# TC37XPD register map
Vendor: Infineon; Series: ATVMC; File version: 100
CPU: other r0p0, little endian, MPU, FPU, vendor SysTick, 4 interrupt priority bits
Registers are 32-bit, read-write, reset 0x0 unless marked. A register's access mark holds for its fields unless they carry their own. Offsets are from the block's base; [hi:lo] are bit positions; lines under a group give offsets from that group; {n}, {i} and the like mark numbered series.

## CAN0 (part 3 of 3) — CAN
Base 0xF0200000
{0x8100+0x400*i} N[{i}] (i=0..3) group
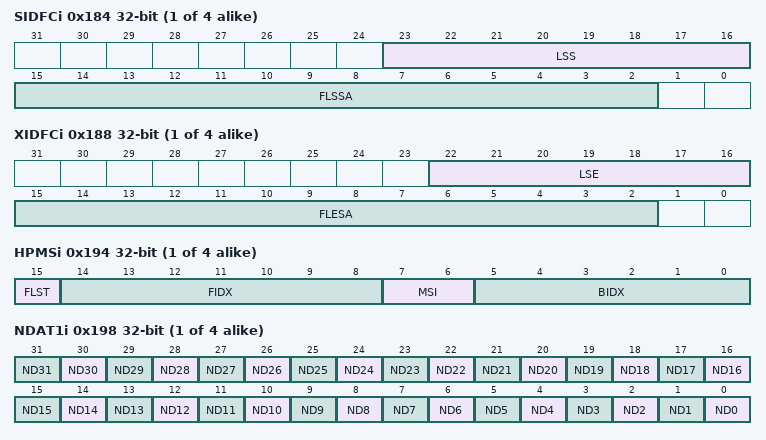
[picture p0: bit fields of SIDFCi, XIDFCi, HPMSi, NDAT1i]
  0x184 SIDFCi — Standard ID Filter Configuration 0 resetvalue={Application Reset:0x0}
    [23:16] LSS — List Size Standard LSS. This bitfield is CCE and INIT protected. Writes will only have effect if both bits are set.
      255=rest255 (128 Message ID filter elements)
    [15:2] FLSSA — Filter List Standard Start Address FLSSA. This bitfield is CCE and INIT protected. Writes will only have effect if both bits are set. Start address of standard Message ID filter list 32 bit word address .
  0x188 XIDFCi — Extended ID Filter Configuration 0 resetvalue={Application Reset:0x0}
    [22:16] LSE — List Size Extended LSE. This bitfield is CCE and INIT protected. Writes will only have effect if both bits are set.
      127=rest127 (64 extended Message ID filter elements)
    [15:2] FLESA — Filter List Extended Start Address FLESA. This bitfield is CCE and INIT protected. Writes will only have effect if both bits are set. Start address of extended Message ID filter list 32 bit word addess .
  0x190 XIDAMi reset 0x1FFFFFFF — Extended ID AND Mask 0 resetvalue={Application Reset:0x1FFFFFFF}
    [28:0] EIDM — Extended ID Mask EIDM. This bitfield is CCE and INIT protected. Writes will only have effect if both bits are set. For acceptance filtering of extended frames the Extended ID AND Mask is ANDed with the Message ID of a received frame. Intended for masking of 29 bit IDs in SAE J1939. With the reset value of all bits set to one the mask is not active.
  0x194 HPMSi ro — High Priority Message Status 0 resetvalue={Application Reset:0x0}
    [15] FLST — Filter List FLST. Indicates the filter list of the matching filter element.
    [14:8] FIDX — Filter Index FIDX. Index of matching filter element. Range is 0 to SIDFC.LSS 160 160 1 resp. XIDFC.LSE 160 160 1.
    [7:6] MSI — Message Storage Indicator MSI
    [5:0] BIDX — Buffer Index BIDX. Index of Rx FIFO element to which the message was stored. Only valid when MSI 1 1 .
  0x198 NDAT1i — New Data 1 0 resetvalue={Application Reset:0x0}
    [n] ND{n} (n=0..31) — New Data in Rx Buffer 31 ND. The flag is set when the respective Rx Buffer has been updated from a received frame. The flags remain set until the Host clears them. A flag is cleared by writing a 8220 1 8221 to the corresponding bit position. Writing a 8220 0 8221 has no effect.
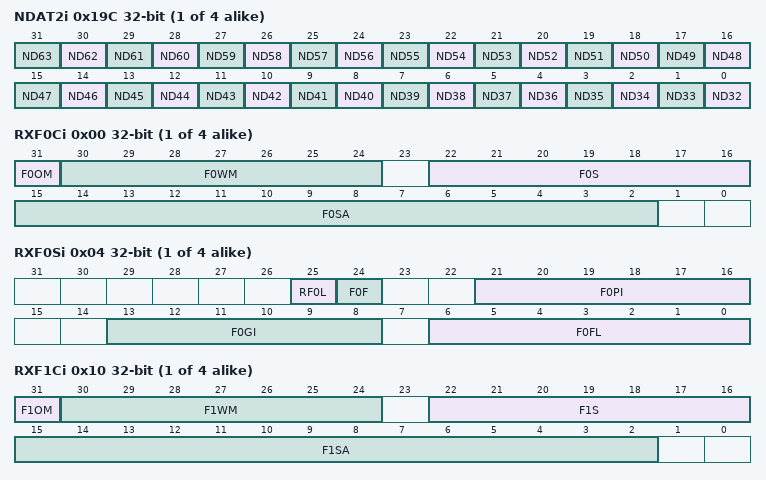
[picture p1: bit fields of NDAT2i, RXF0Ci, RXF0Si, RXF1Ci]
  0x19C NDAT2i — New Data 2 0 resetvalue={Application Reset:0x0}
    [n-32] ND{n} (n=32..63) — New Data in Rx Buffer 63 ND. The flag is set when the respective Rx Buffer has been updated from a received frame. The flags remain set until the Host clears them. A flag is cleared by writing a 8220 1 8221 to the corresponding bit position. Writing a 8220 0 8221 has no effect.
  0x1A0 RX group
    0x00 RXF0Ci — Rx FIFO 0 Configuration 0 resetvalue={Application Reset:0x0}
      [31] F0OM — FIFO 0 Operation Mode F0OM. This bitfield is CCE and INIT protected. Writes will only have effect if both bits are set. FIFO 0 can be operated in blocking or in overwrite mode see CROSSREFERENCE .
      [30:24] F0WM — Rx FIFO 0 Watermark F0WM. This bitfield is CCE and INIT protected. Writes will only have effect if both bits are set.
        127=rest127 (Watermark interrupt disabled)
      [22:16] F0S — Rx FIFO 0 Size F0S. This bitfield is CCE and INIT protected. Writes will only have effect if both bits are set.
        127=rest127 (64 Rx FIFO 0 elements)
      [15:2] F0SA — Rx FIFO 0 Start Address F0SA. This bitfield is CCE and INIT protected. Writes will only have effect if both bits are set. Start address of Rx FIFO 0 in Message RAM 32 bit word address see CROSSREFERENCE .
    0x04 RXF0Si ro — Rx FIFO 0 Status 0 resetvalue={Application Reset:0x0}
      [25] RF0L — Rx FIFO 0 Message Lost RF0L. This bit is a copy of interrupt flag IR.RF0L. When IR.RF0L is reset this bit is also reset. Overwriting the oldest message when RXF0C.F0OM 1 will not set this flag.
      [24] F0F — Rx FIFO 0 Full F0F
      [21:16] F0PI — Rx FIFO 0 Put Index F0PI. Rx FIFO 0 write index pointer range 0 to 63.
      [13:8] F0GI — Rx FIFO 0 Get Index F0GI. Rx FIFO 0 read index pointer range 0 to 63.
      [6:0] F0FL — Rx FIFO 0 Fill Level F0FL. Number of elements stored in Rx FIFO 0 range 0 to 64.
    0x08 RXF0Ai — Rx FIFO 0 Acknowledge 0 resetvalue={Application Reset:0x0}
      [5:0] F0AI — Rx FIFO 0 Acknowledge Index F0AI. After the Host has read a message or a sequence of messages from Rx FIFO 0 it has to write the buffer index of the last element read from Rx FIFO 0 to F0AI. This will set the Rx FIFO 0 Get Index RXF0S.F0GI to F0AI 1 and update the FIFO 0 Fill Level RXF0S.F0FL.
    0x0C RXBCi — Rx Buffer Configuration 0 resetvalue={Application Reset:0x0}
      [15:2] RBSA — Rx Buffer Start Address RBSA. This bitfield is CCE and INIT protected. Writes will only have effect if both bits are set. Configures the start address of the Rx Buffers section in the Message RAM 32 bit word address . Also used to reference debug messages A B C.
    0x10 RXF1Ci — Rx FIFO 1 Configuration 0 resetvalue={Application Reset:0x0}
      [31] F1OM — FIFO 1 Operation Mode F1OM. This bitfield is CCE and INIT protected. Writes will only have effect if both bits are set. FIFO 1 can be operated in blocking or in overwrite mode.
      [30:24] F1WM — Rx FIFO 1 Watermark F1WM. This bitfield is CCE and INIT protected. Writes will only have effect if both bits are set.
        127=rest127 (Watermark interrupt disabled)
      [22:16] F1S — Rx FIFO 1 Size F1S. This bitfield is CCE and INIT protected. Writes will only have effect if both bits are set.
        127=rest127 (64 Rx FIFO 1 elements)
      [15:2] F1SA — Rx FIFO 1 Start Address F1SA. This bitfield is CCE and INIT protected. Writes will only have effect if both bits are set. Start address of Rx FIFO 1 in Message RAM 32 bit word address .
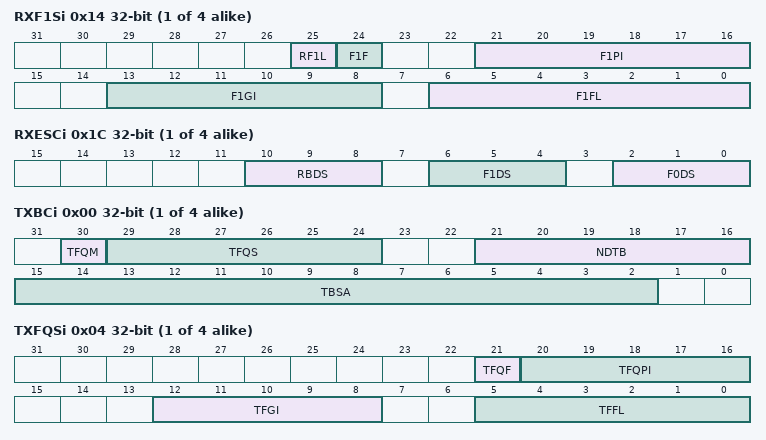
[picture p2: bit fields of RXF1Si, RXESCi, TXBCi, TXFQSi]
    0x14 RXF1Si ro — Rx FIFO 1 Status 0 resetvalue={Application Reset:0x0}
      [25] RF1L — Rx FIFO 1 Message Lost RF1L. This bit is a copy of interrupt flag IR.RF1L. When IR.RF1L is reset this bit is also reset. Overwriting the oldest message when RXF1C.F1OM 1 will not set this flag.
      [24] F1F — Rx FIFO 1 Full F1F
      [21:16] F1PI — Rx FIFO 1 Put Index F1PI. Rx FIFO 1 write index pointer range 0 to 63.
      [13:8] F1GI — Rx FIFO 1 Get Index F1GI. Rx FIFO 1 read index pointer range 0 to 63.
      [6:0] F1FL — Rx FIFO 1 Fill Level F1FL. Number of elements stored in Rx FIFO 1 range 0 to 64.
    0x18 RXF1Ai — Rx FIFO 1 Acknowledge 0 resetvalue={Application Reset:0x0}
      [5:0] F1AI — Rx FIFO 1 Acknowledge Index F1AI. After the Host has read a message or a sequence of messages from Rx FIFO 1 it has to write the buffer index of the last element read from Rx FIFO 1 to F1AI. This will set the Rx FIFO 1 Get Index RXF1S.F1GI to F1AI 1 and update the FIFO 1 Fill Level RXF1S.F1FL
    0x1C RXESCi — Rx Buffer FIFO Element Size Configuration 0 resetvalue={Application Reset:0x0}
      [10:8] RBDS — Rx Buffer Data Field Size RBDS. This bitfield is CCE and INIT protected. Writes will only have effect if both bits are set.
      [6:4] F1DS — Rx FIFO 1 Data Field Size F1DS. This bitfield is CCE and INIT protected. Writes will only have effect if both bits are set.
      [2:0] F0DS — Rx FIFO 0 Data Field Size F0DS. This bitfield is CCE and INIT protected. Writes will only have effect if both bits are set. In case the data field size of an accepted CAN frame exceeds the data field size configured for the matching Rx Buffer or Rx FIFO only the number of bytes as configured by RXESC are stored to the Rx Buffer resp. Rx FIFO element. The rest of the frame s data field is ignored.
  0x1C0 TX group
    0x00 TXBCi — Tx Buffer Configuration 0 resetvalue={Application Reset:0x0}
      [30] TFQM — Tx FIFO Queue Mode TFQM. This bitfield is CCE and INIT protected. Writes will only have effect if both bits are set.
      [29:24] TFQS — Transmit FIFO Queue Size TFQS. This bitfield is CCE and INIT protected. Writes will only have effect if both bits are set.
        63=rest63 (32 Tx Buffers used for Tx FIFO Queue)
      [21:16] NDTB — Number of Dedicated Transmit Buffers NDTB. This bitfield is CCE and INIT protected. Writes will only have effect if both bits are set. Be aware that the sum of TFQS and NDTB may be not greater than 32. There is no check for erroneous configurations. The Tx Buffers section in the Message RAM starts with the dedicated Tx Buffers.
        63=rest63 (32 Dedicated Tx Buffers)
      [15:2] TBSA — Tx Buffers Start Address TBSA. This bitfield is CCE and INIT protected. Writes will only have effect if both bits are set. Start address of Tx Buffers section in Message RAM 32 bit word address .
    0x04 TXFQSi ro — Tx FIFO Queue Status 0 resetvalue={Application Reset:0x0}
      [21] TFQF — Tx FIFO Queue Full TFQF
      [20:16] TFQPI — Tx FIFO Queue Put Index TFQPI. Tx FIFO Queue write index pointer range 0 to 31.
      [12:8] TFGI — Tx FIFO Get Index TFGI. Tx FIFO read index pointer range 0 to 31. Read as zero when Tx Queue operation is configured TXBC.TFQM 1 .
      [5:0] TFFL — Tx FIFO Free Level TFFL. Number of consecutive free Tx FIFO elements starting from TFGI range 0 to 32. Read as zero when Tx Queue operation is configured TXBC.TFQM 8216 1 8217 In case of mixed configurations where dedicated Tx Buffers are combined with a Tx FIFO or a Tx Queue the Put and Get Indices indicate the number of the Tx Buffer starting with the first dedicated Tx Buffers. Example For a configuration of 12 dedicated Tx Buffers and a Tx FIFO of 20 Buffers a Put Index of 15 points to the fourth buffer of the Tx FIFO.
    0x08 TXESCi — Tx Buffer Element Size Configuration 0 resetvalue={Application Reset:0x0}
      [2:0] TBDS — Tx Buffer Data Field Size TBDS. This bitfield is CCE and INIT protected. Writes will only have effect if both bits are set. In case the data length code DLC of a Tx Buffer element is configured to a value higher than the Tx Buffer data field size TXESC.TBDS the bytes not defined by the Tx Buffer are transmitted as 0xCC padding bytes .
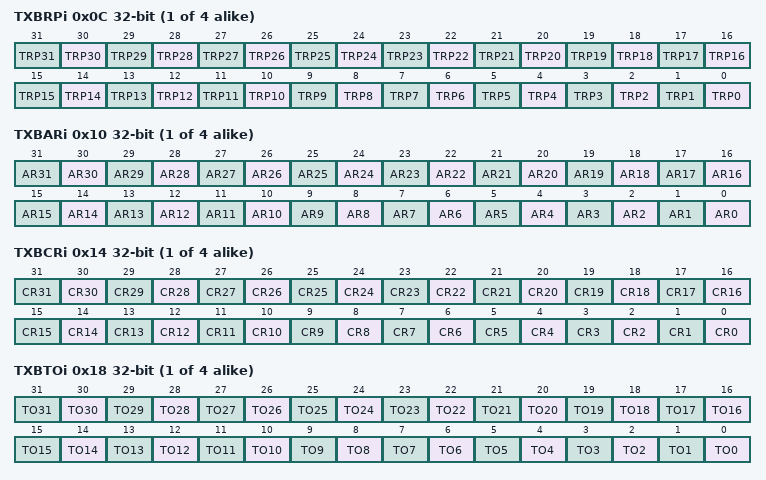
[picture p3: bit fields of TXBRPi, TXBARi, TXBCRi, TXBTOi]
    0x0C TXBRPi ro — Tx Buffer Request Pending 0 resetvalue={Application Reset:0x0}
      [n] TRP{n} (n=0..31) — Transmission Request Pending Tx Buffer 31 TRP
    0x10 TXBARi — Tx Buffer Add Request 0 resetvalue={Application Reset:0x0}
      [n] AR{n} (n=0..31) — Add Request Tx Buffer 31 AR
    0x14 TXBCRi — Tx Buffer Cancellation Request 0 resetvalue={Application Reset:0x0}
      [n] CR{n} (n=0..31) — Cancellation Request Tx Buffer 31 CR
    0x18 TXBTOi ro — Tx Buffer Transmission Occurred 0 resetvalue={Application Reset:0x0}
      [n] TO{n} (n=0..31) — Transmission Occurred Tx Buffer 31 TO
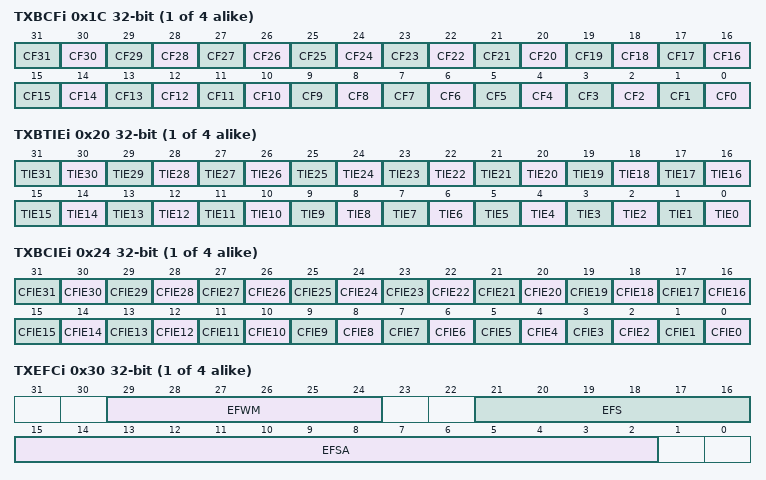
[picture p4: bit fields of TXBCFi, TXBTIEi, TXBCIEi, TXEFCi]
    0x1C TXBCFi ro — Tx Buffer Cancellation Finished 0 resetvalue={Application Reset:0x0}
      [n] CF{n} (n=0..31) — Cancellation Finished Tx Buffer 31 CF
    0x20 TXBTIEi — Tx Buffer Transmission Interrupt Enable 0 resetvalue={Application Reset:0x0}
      [n] TIE{n} (n=0..31) — Transmission Interrupt Enable Tx Buffer 31 TIE
    0x24 TXBCIEi — Tx Buffer Cancellation Finished Interrupt Enable 0 resetvalue={Application Reset:0x0}
      [n] CFIE{n} (n=0..31) — Cancellation Finished Interrupt Enable Tx Buffer 31 CFIE
    0x30 TXEFCi — Tx Event FIFO Configuration 0 resetvalue={Application Reset:0x0}
      [29:24] EFWM — Event FIFO Watermark EFWM. This bitfield is CCE and INIT protected. Writes will only have effect if both bits are set.
        63=rest63 (Watermark interrupt disabled)
      [21:16] EFS — Event FIFO Size EFS. This bitfield is CCE and INIT protected. Writes will only have effect if both bits are set. The Tx Event FIFO elements are indexed from 0 to EFS 1
        63=rest63 (32 Tx Event FIFO elements)
      [15:2] EFSA — Event FIFO Start Address EFSA. This bitfield is CCE and INIT protected. Writes will only have effect if both bits are set. Start address of Tx Event FIFO in Message RAM 32 bit word address .
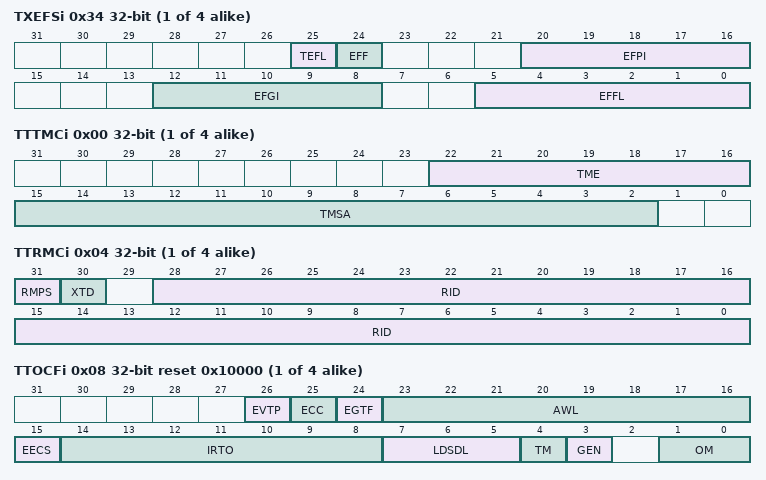
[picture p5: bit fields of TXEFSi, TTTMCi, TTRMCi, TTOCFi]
    0x34 TXEFSi ro — Tx Event FIFO Status 0 resetvalue={Application Reset:0x0}
      [25] TEFL — Tx Event FIFO Element Lost TEFL. This bit is a copy of interrupt flag IR.TEFL. When IR.TEFL is reset this bit is also reset.
      [24] EFF — Event FIFO Full EFF
      [20:16] EFPI — Event FIFO Put Index EFPI. Tx Event FIFO write index pointer range 0 to 31.
      [12:8] EFGI — Event FIFO Get Index EFGI. Tx Event FIFO read index pointer range 0 to 31.
      [5:0] EFFL — Event FIFO Fill Level EFFL. Number of elements stored in Tx Event FIFO range 0 to 32.
    0x38 TXEFAi — Tx Event FIFO Acknowledge 0 resetvalue={Application Reset:0x0}
      [4:0] EFAI — Event FIFO Acknowledge Index EFAI. After the Host has read an element or a sequence of elements from the Tx Event FIFO it has to write the index of the last element read from Tx Event FIFO to EFAI. This will set the Tx Event FIFO Get Index TXEFS.EFGI to EFAI 160 160 1 and update the FIFO 0 Fill Level TXEFS.EFFL.
  0x200 TT group
    0x00 TTTMCi — TT Trigger Memory Configuration 0 resetvalue={Application Reset:0x0}
      [22:16] TME — Trigger Memory Elements TME. This bitfield is CCE and INIT protected. Writes will only have effect if both bits are set.
        127=rest127 (64 Trigger Memory elements)
      [15:2] TMSA — Trigger Memory Start Address TMSA. This bitfield is CCE and INIT protected. Writes will only have effect if both bits are set. Start address of Trigger Memory in Message RAM.
    0x04 TTRMCi — TT Reference Message Configuration 0 resetvalue={Application Reset:0x0}
      [31] RMPS — Reference Message Payload Select RMPS. This bitfield is CCE and INIT protected. Writes will only have effect if both bits are set. Ignored in case of time slaves.
      [30] XTD — Extended Identifier XTD. This bitfield is CCE and INIT protected. Writes will only have effect if both bits are set.
      [28:0] RID — Reference Identifier RID. This bitfield is CCE and INIT protected. Writes will only have effect if both bits are set. Identifier transmitted with reference message and used for reference message filtering. Standard or extended reference identifier depending on bit XTD. A standard identifier has to be written to ID 28 18 .
    0x08 TTOCFi reset 0x10000 — TT Operation Configuration 0 resetvalue={Application Reset:0x10000}
      [26] EVTP — Event Trigger Polarity EVTP. This bitfield is CCE and INIT protected. Writes will only have effect if both bits are set.
      [25] ECC — Enable Clock Calibration ECC. This bitfield is CCE and INIT protected. Writes will only have effect if both bits are set.
      [24] EGTF — Enable Global Time Filtering EGTF. This bitfield is CCE and INIT protected. Writes will only have effect if both bits are set.
      [23:16] AWL — Application Watchdog Limit AWL. This bitfield is CCE and INIT protected. Writes will only have effect if both bits are set. The application watchdog can be disabled by programming AWL to 0x00. Maximum time after which the application has to serve the application watchdog. The application watchdog is incremented once each 256 NTUs.
      [15] EECS — Enable External Clock Synchronization EECS. This bitfield is CCE and INIT protected. Writes will only have effect if both bits are set. If enabled TUR configuration TURCF.NCL only may be updated during TTCAN operation.
      [14:8] IRTO — Initial Reference Trigger Offset IRTO. This bitfield is CCE and INIT protected. Writes will only have effect if both bits are set. Positive offset range from 0 to 127
      [7:5] LDSDL — LD of Synchronization Deviation Limit LDSDL. This bitfield is CCE and INIT protected. Writes will only have effect if both bits are set. The Synchronization Deviation Limit SDL is configured by its dual logarithm LDSDL with SDL 2 LDSDL 160 160 5 . It should not exceed the clock tolerance given by the CAN bit timing configuration. LD of Synchronization Deviation Limit SDL 8804 32 8230 4096
      [4] TM — Time Master TM. This bitfield is CCE and INIT protected. Writes will only have effect if both bits are set.
      [3] GEN — Gap Enable GEN. This bitfield is CCE and INIT protected. Writes will only have effect if both bits are set.
      [1:0] OM — Operation Mode OM. This bitfield is CCE and INIT protected. Writes will only have effect if both bits are set.
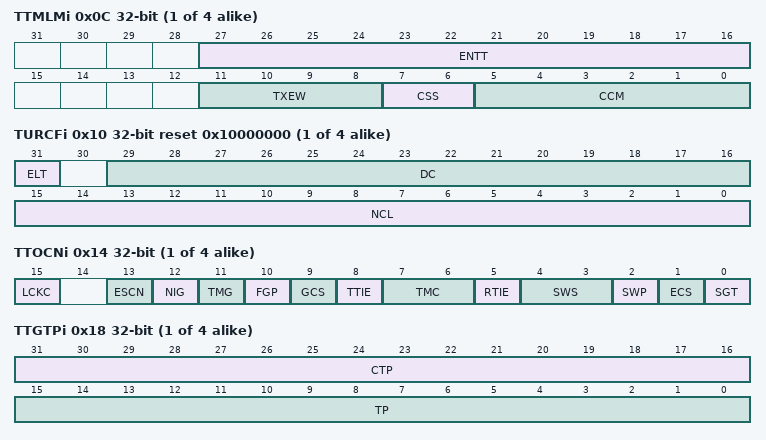
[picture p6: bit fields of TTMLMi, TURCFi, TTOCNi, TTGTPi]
    0x0C TTMLMi — TT Matrix Limits 0 resetvalue={Application Reset:0x0}
      [27:16] ENTT — Expected Number of Tx Triggers ENTT. This bitfield is CCE and INIT protected. Writes will only have effect if both bits are set. Expected number of Tx Triggers in one Matrix Cycle
      [11:8] TXEW — Tx Enable Window TXEW. This bitfield is CCE and INIT protected. Writes will only have effect if both bits are set. Length of Tx enable window 1 16 NTU cycles
      [7:6] CSS — Cycle Start Synchronization CSS. This bitfield is CCE and INIT protected. Writes will only have effect if both bits are set. Enables sync pulse output at start of cycle.
      [5:0] CCM — Cycle Count Max CCM. This bitfield is CCE and INIT protected. Writes will only have effect if both bits are set. ISO 11898 4 5.2.1 requires that only the listed cycle count values are configured. Other values are possible but may lead to inconsistent matrix cycles.
    0x10 TURCFi reset 0x10000000 — TUR Configuration 0 resetvalue={Application Reset:0x10000000}
      [31] ELT — Enable Local Time ELT. This bitfield is CCE and INIT protected. Writes will only have effect if both bits are set. Local time is started by setting ELT. It remains active until ELT is reset or until the next hardware reset. TURCF.DC is locked when TURCF.ELT 8216 1 8217 . If ELT is written to 8216 0 8217 the readable value will stay at 8216 1 8217 until the new value has been synchronized into the CAN clock domain. During this time write access to the other bits of the register remains locked.
      [29:16] DC — Denominator Configuration DC. This bitfield is CCE and INIT protected. Writes will only have effect if both bits are set.
      [15:0] NCL — Numerator Configuration Low NCL. This bitfield is CCE and INIT protected. Writes will only have effect if both bits are set. Write access to the TUR Numerator Configuration Low is only possible during configuration with TURCF.ELT 8216 0 8217 or if TTOCF.EECS external clock synchronization enabled is set. When a new value for NCL is written outside TT Configuration Mode the new value takes effect when TTOST.WECS is cleared to 8216 0 8217 . NCL is locked TTOST.WECS is 8216 1 8217 . If NC 160 lt 160 7 160 x 160 DC in TTCAN Level 1 then it is required that subsequent time marks in the Trigger Memory must differ by at least 2 NTU.
    0x14 TTOCNi access per field — TT Operation Control 0 resetvalue={Application Reset:0x0}
      [15] LCKC ro — TT Operation Control Register Locked LCKC. Set by a write access to register TTOCN. Reset when the updated configuration has been synchronized into the CAN clock domain.
      [13] ESCN rw — External Synchronization Control ESCN. If enabled the M CAN synchronizes its cycle time phase to an external event signalled by a rising edge at the event trigger.
      [12] NIG rw — Next is Gap NIG. This bit can only be set when the M CAN is the actual Time Master and when it is configured for external event synchronized time triggered operation TTOCF.GEN 8216 1 8217
      [11] TMG rw — Time Mark Gap TMG
      [10] FGP rw — Finish Gap FGP. Set by the CPU reset by each reference message
      [9] GCS rw — Gap Control Select GCS
      [8] TTIE rw — Trigger Time Mark Interrupt Pulse Enable TTIE. External time mark events are configured by trigger memory element TMEX. A trigger time mark interrupt pulse is generated when the trigger memory element becomes active and the M CAN is in synchronization state In Schedule or In Gap.
      [7:6] TMC rw — Register Time Mark Compare TMC. When changing the time mark reference cycle local global time it is recommended to first write TMC 8220 00 8221 then reconfigure TTTMK and finally set TMC to the intended time reference.
      [5] RTIE rw — Register Time Mark Interrupt Pulse Enable RTIE. Register time mark interrupts are configured by register TTTMK. A register time mark interrupt pulse with the length of one TTCAN clock period is generated when the time referenced by TTOCN.TMC cycle local or global equals TTTMK.TM independent of the synchronization state.
      [4:3] SWS rw — Stop Watch Source SWS
      [2] SWP rw — Stop Watch Polarity SWP
      [1] ECS rw — External Clock Synchronization ECS. Writing a 8216 1 8217 to ECS sets TTOST.WECS if the node is the actual Time Master. ECS is reset after one Host clock period. The external clock synchronization takes effect at the start of the next basic cycle.
      [0] SGT rw — Set Global time SGT. Writing a 8216 1 8217 to SGT sets TTOST.WGDT if the node is the actual Time Master. SGT is reset after one Host clock period. The global time preset takes effect when the node transmits the next reference message with the Master Ref Mark modified by the preset value written to TTGTP.
    0x18 TTGTPi — TT Global Time Preset 0 resetvalue={Application Reset:0x0}
      [31:16] CTP — Cycle Time Target Phase CTP. CTP is write protected while TTOCN.ESCN or TTOST.SPL are set.
      [15:0] TP — Time Preset TP. CTP is write protected while TTOCN.ESCN or TTOST.SPL are set.
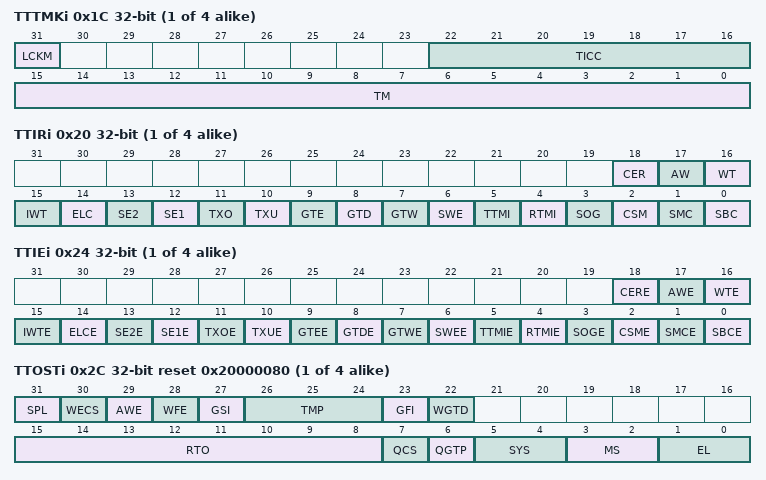
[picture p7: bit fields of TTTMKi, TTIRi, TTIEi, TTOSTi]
    0x1C TTTMKi access per field — TT Time Mark 0 resetvalue={Application Reset:0x0}
      [31] LCKM ro — TT Time Mark Register Locked LCKM. Always set by a write access to registers TTOCN. Set by write access to register TTTMK when TTOCN.TMC 8800 quot 00 8221 . Reset when the registers have been synchronized into the CAN clock domain.
      [22:16] TICC rw — Time Mark Cycle Code TICC. Cycle count for which the time mark is valid.
      [15:0] TM rw — Time Mark TM. When using byte access to register TTTMK it is recommended to first disable the time mark compare function TTOCN.TMC 8220 00 8221 to avoid compares on inconsistent register values.
    0x20 TTIRi — TT Interrupt Register 0 resetvalue={Application Reset:0x0}
      [18] CER — Configuration Error CER. Trigger out of order.
      [17] AW — Application Watchdog AW
      [16] WT — Watch Trigger WT
      [15] IWT — Initialization Watch Trigger IWT. The initialization is restarted by resetting IWT.
      [14] ELC — Error Level Changed ELC. Not set when error level changed during initialization.
      [13] SE2 — Scheduling Error 2 SE2
      [12] SE1 — Scheduling Error 1 SE1
      [11] TXO — Tx Count Overflow TXO
      [10] TXU — Tx Count Underflow TXU
      [9] GTE — Global Time Error GTE. Synchronization deviation SD exceeds limit specified by TTOCF.LDSDL TTCAN Level 160 0 2 only.
      [8] GTD — Global Time Discontinuity GTD
      [7] GTW — Global Time Wrap GTW
      [6] SWE — Stop Watch Polarity SWE
      [5] TTMI — Trigger Time Mark Event Internal TTMI. Internal time mark events are configured by trigger memory element TMIN. Set when the trigger memory element becomes active and the M CAN is in synchronization state In Gap or In Schedule.
      [4] RTMI — Register Time Mark Interrupt RTMI. Set when time referenced by TTOCN.TMC cycle local or global equals TTTMK.TM independent of the synchronization state.
      [3] SOG — Start of Gap SOG
      [2] CSM — Change of Synchronization Mode CSM
      [1] SMC — Start of Matrix Cycle SMC
      [0] SBC — Start of Basic Cycle SBC
    0x24 TTIEi — TT Interrupt Enable 0 resetvalue={Application Reset:0x0}
      [18] CERE — Configuration Error Interrupt Enable CERE
      [17] AWE — Application Watchdog Interrupt Enable AWE
      [16] WTE — Watch Trigger Interrupt Enable WTE
      [15] IWTE — Initialization Watch Trigger Interrupt Enable IWTE
      [14] ELCE — Change Error Level Interrupt Enable ELCE
      [13] SE2E — Scheduling Error 2 Interrupt Enable SE2E
      [12] SE1E — Scheduling Error 1 Interrupt Enable SE1E
      [11] TXOE — Tx Count Overflow Interrupt Enable TXOE
      [10] TXUE — Tx Count Underflow Interrupt Enable TXUE
      [9] GTEE — Global Time Error Interrupt Enable GTEE
      [8] GTDE — Global Time Discontinuity Interrupt Enable GTDE
      [7] GTWE — Global Time Wrap Interrupt Enable GTWE
      [6] SWEE — Stop Watch Polarity Interrupt Enable SWEE
      [5] TTMIE — Trigger Time Mark Event Internal Interrupt Enable TTMIE
      [4] RTMIE — Register Time Mark Interrupt Enable RTMIE
      [3] SOGE — Start of Gap Interrupt Enable SOGE
      [2] CSME — Change of Synchronization Mode Interrupt Enable CSME
      [1] SMCE — Start of Matrix Cycle Interrupt Enable SMCE
      [0] SBCE — Start of Basic Cycle Interrupt Enable SBCE
    0x2C TTOSTi ro reset 0x20000080 — TT Operation Status 0 resetvalue={Application Reset:0x20000080}
      [31] SPL — Schedule Phase Lock SPL. The bit is valid only when external synchronization is enabled TTOCN.ESCN 8216 1 8217 . In this case it signals that the difference between cycle time configured by TTGTP.CTP and the cycle time at the rising edge at the event trigger is less or equal 9 NTU.
      [30] WECS — Wait for External Clock Synchronization WECS
      [29] AWE — Application Watchdog Event AWE. The application watchdog is served by reading TTOST. When the watchdog is not served in time bit AWE is set all TTCAN communication is stopped and the M CAN is set into Bus Monitoring Mode.
      [28] WFE — Wait for Event WFE
      [27] GSI — Gap Started Indicator GSI
      [26:24] TMP — Time Master Priority TMP
      [23] GFI — Gap Finished Indicator GFI. Set when the CPU writes TTOCN.FGP or by a time mark interrupt if TMG 160 160 8216 1 8217 or via event trigger input if TTOCN.GCS 160 160 8216 1 8217 . Not set by Ref Trigger Gap or when Gap is finished by another node sending a reference message.
      [22] WGTD — Wait for Global Time Discontinuity WGTD
      [15:8] RTO — Reference Trigger Offset RTO. The Reference Trigger Offset value is a signed integer with a range from 127 0x81 to 127 0x7F . There is no notification when the lower limit of 127 is reached. In case the M CAN becomes Time Master MS 1 0 8220 11 8221 the reset of RTO is delayed due to synchronization between Host and CAN clock domain. For time slaves the value configured by TTOCF.IRTO is read. Actual Reference Trigger offset value
      [7] QCS — Quality of Clock Speed QCS. Only relevant in TTCAN Level 160 0 and Level 160 2 otherwise fixed to 8216 1 8217 .
      [6] QGTP — Quality of Global Time Phase QGTP. Only relevant in TTCAN Level 160 0 and Level 160 2 otherwise fixed to 8216 0 8217 .
      [5:4] SYS — Synchronization State SYS
      [3:2] MS — Master State MS
      [1:0] EL — Error Level EL
    0x30 TURNAi ro reset 0x10000 — TUR Numerator Actual 0 resetvalue={Application Reset:0x10000}
      [17:0] NAV — Numerator Actual Value NAV
        0x3FFFF=rest262143 (Illegal value)
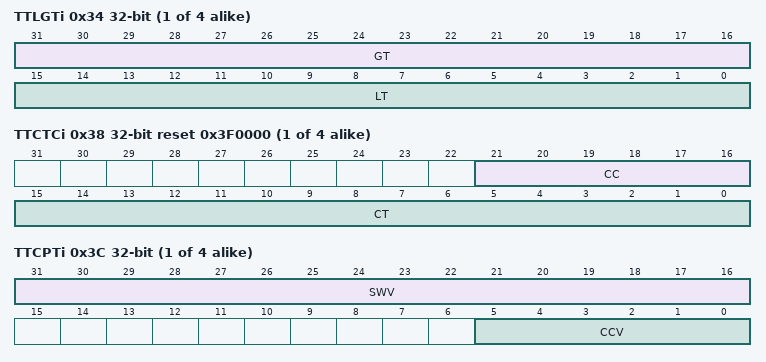
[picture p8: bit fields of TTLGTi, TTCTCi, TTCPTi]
    0x34 TTLGTi ro — TT Local Global Time 0 resetvalue={Application Reset:0x0}
      [31:16] GT — Global Time GT. Non fractional part of the sum of the node 8217 s local time and its local offset. Global time value of TTCAN network
      [15:0] LT — Local Time LT. Non fractional part of local time incremented once each local NTU. Local time value of TTCAN node
    0x38 TTCTCi ro reset 0x3F0000 — TT Cycle Time Count 0 resetvalue={Application Reset:0x3F0000}
      [21:16] CC — Cycle Count CC. Number of actual Basic Cycle in the System Matrix
      [15:0] CT — Cycle Time CT. Non fractional part of the difference of the node 8217 s local time and Ref Mark. Cycle time value of TTCAN Basic Cycle
    0x3C TTCPTi ro — TT Capture Time 0 resetvalue={Application Reset:0x0}
      [31:16] SWV — Stop Watch Value SWV. On a rising falling edge as configured via TTOCN.SWP at the Stop Watch Trigger when TTOCN.SWS is 8800 8220 00 8221 and TTIR.SWE is 8216 0 8217 the actual time value as selected by TTOCN.SWS cycle local global is copied to SWV and TTIR.SWE will be set to 8216 1 8217 . Capturing of the next stop watch value is enabled by resetting TTIR.SWE. Captured Stop Watch value
      [5:0] CCV — Cycle Count Value CCV. Cycle count value captured together with SWV. Captured cycle count value
    0x40 TTCSMi ro — TT Cycle Sync Mark 0 resetvalue={Application Reset:0x0}
      [15:0] CSM — Cycle Sync Mark CSM. The Cycle Sync Mark is measured in cycle time. It is updated when the reference message becomes valid and retains its value until the next reference message becomes valid. Captured cycle time
